# CH592SFR register map
Vendor: WCH Ltd.; Series: CH59x; File version: 1.0
CPU: RISC-V r0p0, little endian, no MPU, no FPU, 2 interrupt priority bits
Registers are 8-bit, Read or Write, reset 0x0 unless marked. A register's access mark holds for its fields unless they carry their own. Offsets are from the block's base; [hi:lo] are bit positions; {n}, {i} and the like mark numbered series.

## PFIC — Program Fast Interrupt Controller
Base 0xE000E000
0x00 R32_PFIC_ISR1 32-bit ro reset 0xC — RO,Interrupt Status Register 1
  [31:12] INTENSTA — Interrupt ID Status
0x04 R32_PFIC_ISR2 32-bit ro — RO,Interrupt Status Register 2
  [3:0] INTENSTA — Interrupt ID Status
0x20 R32_PFIC_IPR1 32-bit ro — RO,Interrupt Pending Register 1
  [31:12] PENDSTA
0x24 R32_PFIC_IPR2 32-bit ro — RO,Interrupt Pending Register 2
  [3:0] PENDSTA
0x40 R32_PFIC_ITHRESDR 32-bit — RW,Interrupt Priority Register
  [7:0] THRESHOLD — RW,THRESHOLD
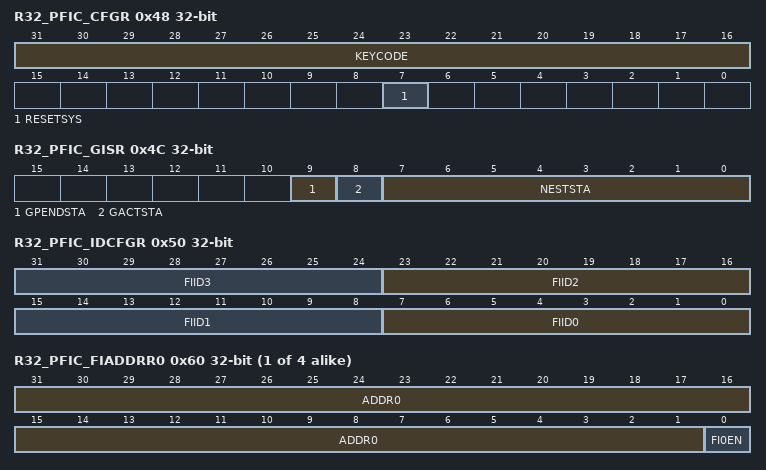
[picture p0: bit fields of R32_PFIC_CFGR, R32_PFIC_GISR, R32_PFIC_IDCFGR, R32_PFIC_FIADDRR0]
0x48 R32_PFIC_CFGR 32-bit wo — Interrupt Config Register
  [31:16] KEYCODE — WO,KEYCODE
  [7] RESETSYS — WO,RESETSYS
0x4C R32_PFIC_GISR 32-bit ro — Interrupt Global Register
  [9] GPENDSTA — RO,GPENDSTA
  [8] GACTSTA — RO,GACTSTA
  [7:0] NESTSTA — RO,NESTSTA
0x50 R32_PFIC_IDCFGR 32-bit — RW,Interrupt Fast ID Config Register
  [8n+7:8n] FIID{n} (n=0..3) — RW,FIID{n}
{0x60+4i} R32_PFIC_FIADDRR{i} 32-bit (i=0..3) — Interrupt {i} address Register
  [31:1] ADDR{i} — RW,ADDR{i}
  [0] FI{i}EN — RW,Fast interrupt channel {i} enable bit
0x100 R32_PFIC_IENR1 32-bit wo — Interrupt Setting Register
  [31:12] INTEN — RW1,INTEN
0x104 R32_PFIC_IENR2 32-bit wo — Interrupt Setting Register
  [3:0] INTEN — RW1,INTEN
0x180 R32_PFIC_IRER1 32-bit wo — Interrupt Clear Register
  [31:12] INTRESET — RW1,INTRESET
0x184 R32_PFIC_IRER2 32-bit wo — Interrupt Clear Register
  [3:0] INTRESET — RW1,INTRESET
0x200 R32_PFIC_IPSR1 32-bit wo — Interrupt Pending Register
  [31:12] PENDSET — RW1,PENDSET
0x204 R32_PFIC_IPSR2 32-bit wo — Interrupt Pending Register
  [3:0] PENDSET — RW1,PENDSET
0x280 R32_PFIC_IPRR1 32-bit wo — Interrupt Pending Clear Register
  [31:12] PENDRESET — RW1,PENDRESET
0x284 R32_PFIC_IPRR2 32-bit wo — Interrupt Pending Clear Register
  [3:0] PENDRESET — RW1,PENDRESET
0x300 R32_PFIC_IACTR1 32-bit — Interrupt ACTIVE Register
  [31:12] IACTS — RW1,IACTS
0x304 R32_PFIC_IACTR2 32-bit — Interrupt ACTIVE Register
  [3:0] IACTS — RW1,IACTS
0x400 R32_PFIC_IPRIOR0 32-bit — Interrupt Priority configuration Register 0
  [31:0] IPRIOR0 — RW,Interrupt priority for number 0-3
{0x400+0x20*i} R32_PFIC_IPRIOR{i} 32-bit (i=1..7) — Interrupt Priority configuration Register {i}
  [31:0] IPRIOR{i} — >RW,Interrupt priority for number {4i}-{4i+3}
0x500 R32_PFIC_IPRIOR8 32-bit — Interrupt Priority configuration Register 8
  [31:0] IPRIOR8 — RW,Interrupt priority for number 32-35
0x520 R32_PFIC_IPRIOR9 32-bit — Interrupt Priority configuration Register 9
  [31:0] IPRIOR9 — >RW,Interrupt priority for number 36-39
0x540 R32_PFIC_IPRIOR10 32-bit — Interrupt Priority configuration Register 10
  [31:0] IPRIOR10 — >RW,Interrupt priority for number 40-43
{0x400+0x20*i} R32_PFIC_IPRIOR{i} 32-bit (i=11..19) — Interrupt Priority configuration Register {i}
  [31:0] IPRIOR{i} — RW,Interrupt priority for number {4i}-{4i+3}
0x680 R32_PFIC_IPRIOR20 32-bit — Interrupt Priority configuration Register 20
  [31:0] IPRIOR20 — RW,RW,Interrupt priority for number 80-83
{0x400+0x20*i} R32_PFIC_IPRIOR{i} 32-bit (i=21..53) — Interrupt Priority configuration Register {i}
  [31:0] IPRIOR{i} — RW,Interrupt priority for number {4i}-{4i+3}
0xAD0 R32_PFIC_IPRIOR54 32-bit — Interrupt Priority configuration Register 54
  [31:0] IPRIOR54 — RW,Interrupt priority for number 216-219
{0x400+0x20*i} R32_PFIC_IPRIOR{i} 32-bit (i=55..61) — Interrupt Priority configuration Register {i}
  [31:0] IPRIOR{i} — RW,Interrupt priority for number {4i}-{4i+3}
0xBE0 R32_PFIC_IPRIOR62 32-bit — Interrupt Priority configuration Register 62
  [31:0] IPRIOR62 — RW,Interrupt priority for number 248-251
0xC00 R32_PFIC_IPRIOR63 32-bit — Interrupt Priority configuration Register 63
  [31:0] IPRIOR63 — RW,Interrupt priority for number 252-255
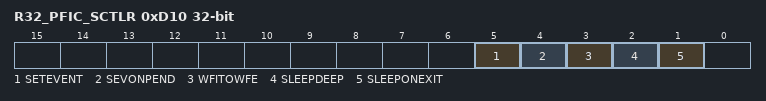
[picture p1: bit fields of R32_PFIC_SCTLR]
0xD10 R32_PFIC_SCTLR 32-bit — System Control Register
  [5] SETEVENT — WO,SETEVENT
  [4] SEVONPEND — RW,SEVONPEND
  [3] WFITOWFE — RW,WFITOWFE
  [2] SLEEPDEEP — RW,SLEEPDEEP
  [1] SLEEPONEXIT — RW,SLEEPONEXIT
